# PIC32CZ2051CA90144 device description
Architecture: CORTEX-M7; Family: PIC32C; Series: PIC32CZCA90
Registers are 32-bit, read-write, reset 0x0 unless marked. A register's access mark holds for its fields unless they carry their own. Offsets are from the block's base; [hi:lo] are bit positions; {n}, {i} and the like mark numbered series; 'fields as' and 'values as' point back to an identical list.

## CoreDebug
Instances: CoreDebug 0xE000ED00
0x30 DFSR — Debug Fault Status Register
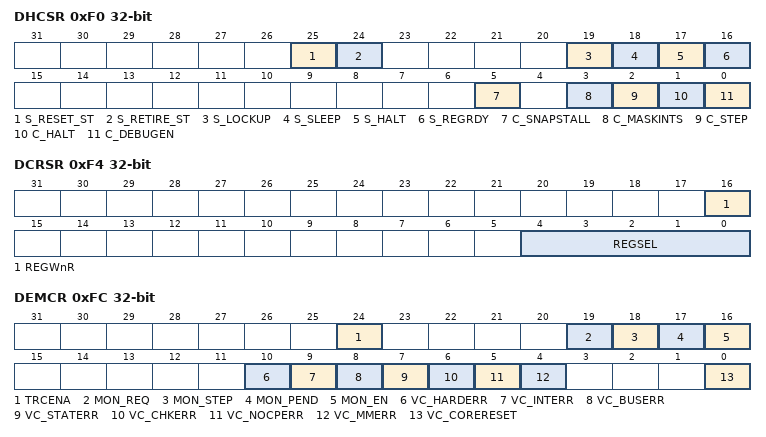
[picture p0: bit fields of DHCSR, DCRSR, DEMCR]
0xF0 DHCSR — Debug Halting Control and Status Register
  [25] S_RESET_ST, [24] S_RETIRE_ST, [19] S_LOCKUP, [18] S_SLEEP, [17] S_HALT, [16] S_REGRDY, [5] C_SNAPSTALL, [3] C_MASKINTS, [2] C_STEP, [1] C_HALT, [0] C_DEBUGEN
0xF4 DCRSR wo reset not defined — Debug Core Register Selector Register
  [16] REGWnR, [4:0] REGSEL
0xF8 DCRDR reset not defined — Debug Core Register Data Register
0xFC DEMCR — Debug Exception and Monitor Control Register
  [24] TRCENA, [19] MON_REQ, [18] MON_STEP, [17] MON_PEND, [16] MON_EN, [10] VC_HARDERR, [9] VC_INTERR, [8] VC_BUSERR, [7] VC_STATERR, [6] VC_CHKERR, [5] VC_NOCPERR, [4] VC_MMERR, [0] VC_CORERESET

## DWT — Data Watchpoint and Trace Register
Instances: DWT 0xE0001000
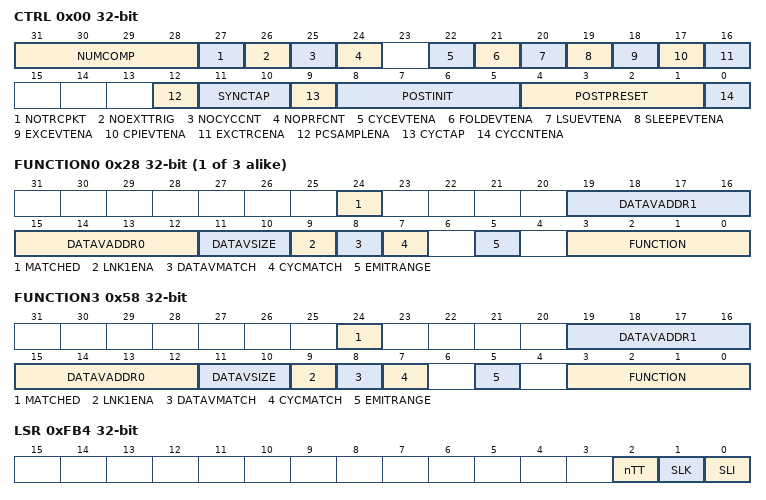
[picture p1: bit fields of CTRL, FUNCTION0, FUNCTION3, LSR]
0x00 CTRL reset not defined — Control Register
  [31:28] NUMCOMP, [27] NOTRCPKT, [26] NOEXTTRIG, [25] NOCYCCNT, [24] NOPRFCNT, [22] CYCEVTENA, [21] FOLDEVTENA, [20] LSUEVTENA, [19] SLEEPEVTENA, [18] EXCEVTENA, [17] CPIEVTENA, [16] EXCTRCENA, [12] PCSAMPLENA, [11:10] SYNCTAP, [9] CYCTAP, [8:5] POSTINIT, [4:1] POSTPRESET, [0] CYCCNTENA
0x04 CYCCNT — Cycle Count Register
0x08 CPICNT reset not defined — CPI Count Register
  [7:0] CPICNT
0x0C EXCCNT reset not defined — Exception Overhead Count Register
  [7:0] EXCCNT
0x10 SLEEPCNT reset not defined — Sleep Count Register
  [7:0] SLEEPCNT
0x14 LSUCNT reset not defined — LSU Count Register
  [7:0] LSUCNT
0x18 FOLDCNT reset not defined — Folded-instruction Count Register
  [7:0] FOLDCNT
0x1C PCSR ro reset not defined — Program Counter Sample Register
{0x20+0x10*i} COMP{i} reset not defined (i=0..3) — Comparator Register {i}
{0x24+0x10*i} MASK{i} reset not defined (i=0..3) — Mask Register {i}
  [4:0] MASK
{0x28+0x10*i} FUNCTION{i} (i=0..2) — Function Register {i}
  [24] MATCHED, [19:16] DATAVADDR1, [15:12] DATAVADDR0, [11:10] DATAVSIZE, [9] LNK1ENA, [8] DATAVMATCH, [7] CYCMATCH, [5] EMITRANGE, [3:0] FUNCTION
0x58 FUNCTION3 reset not defined — Function Register 3
  fields as FUNCTION0
0xFB0 LAR wo reset not defined — DWT Software Lock Access Register
  [31:0] KEY — Lock access control
    0xC5ACCE55=UNLOCK (Unlock key value)
0xFB4 LSR ro reset not defined — DWT Software Lock Status Register
  [2] nTT — Not thirty-two bit
  [1] SLK — Software Lock status
  [0] SLI — Software Lock implemented
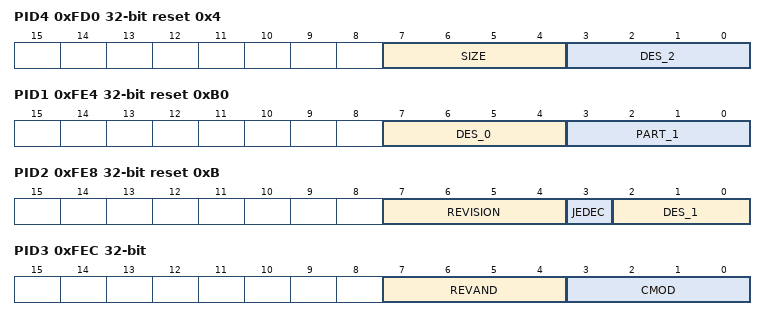
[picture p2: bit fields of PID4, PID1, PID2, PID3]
0xFD0 PID4 ro reset 0x4 — DWT Peripheral Identification Register 4
  [7:4] SIZE — 4KB count
  [3:0] DES_2 — JEP106 continuation code
{0xFC0+4i} PID{i} ro (i=5..7) — DWT Peripheral Identification Register {i}
0xFE0 PID0 ro reset 0x2 — DWT Peripheral Identification Register 0
  [7:0] PART_0 — Part number bits[7:0]
0xFE4 PID1 ro reset 0xB0 — DWT Peripheral Identification Register 1
  [7:4] DES_0 — JEP106 identification code bits [3:0]
  [3:0] PART_1 — Part number bits[11:8]
0xFE8 PID2 ro reset 0xB — DWT Peripheral Identification Register 2
  [7:4] REVISION — Component revision
  [3] JEDEC — JEDEC assignee value is used
  [2:0] DES_1 — JEP106 identification code bits[6:4]
0xFEC PID3 ro — DWT Peripheral Identification Register 3
  [7:4] REVAND
  [3:0] CMOD — Customer Modified
0xFF0 CID0 ro reset 0xD — DWT Component Identification Register 0
  [7:0] PRMBL_0 — CoreSight component identification preamble
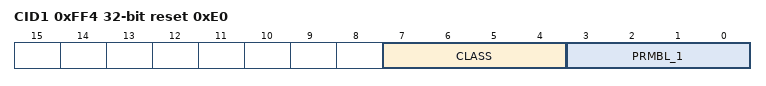
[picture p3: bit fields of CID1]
0xFF4 CID1 ro reset 0xE0 — DWT Component Identification Register 1
  [7:4] CLASS — CoreSight component class
  [3:0] PRMBL_1 — CoreSight component identification preamble
0xFF8 CID2 ro reset 0x5 — DWT Component Identification Register 2
  [7:0] PRMBL_2 — CoreSight component identification preamble
0xFFC CID3 ro reset 0xB1 — DWT Component Identification Register 3
  [7:0] PRMBL_3 — CoreSight component identification preamble

## Notices in the file
Copyright (c) 2021 Microchip Technology Inc.
SPDX-License-Identifier: Apache-2.0
Licensed under the Apache License, Version 2.0 (the "License");
you may not use this file except in compliance with the License.
You may obtain a copy of the License at
http://www.apache.org/licenses/LICENSE-2.0
Unless required by applicable law or agreed to in writing, software
distributed under the License is distributed on an "AS IS" BASIS,
WITHOUT WARRANTIES OR CONDITIONS OF ANY KIND, either express or implied.
See the License for the specific language governing permissions and
limitations under the License.
